# PIC32MZ2048EFM144 register map
Vendor: Microchip
Registers are 32-bit, read-write, reset 0x0 unless marked. A register's access mark holds for its fields unless they carry their own. Addresses are absolute, and some are shared; only a register's first bit layout is shown; [hi:lo] are bit positions; {n}, {i} and the like mark numbered series.

## UART4
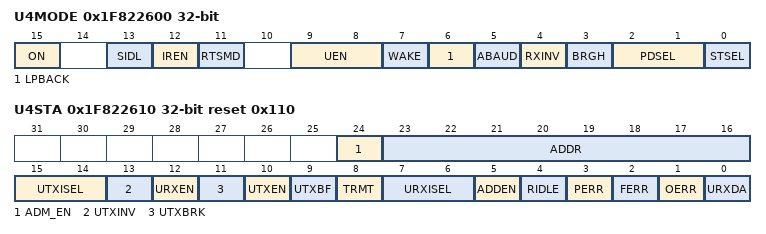
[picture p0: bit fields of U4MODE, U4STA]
0x1F822600 U4MODE
  [15] ON, [13] SIDL, [12] IREN, [11] RTSMD, [9:8] UEN, [7] WAKE, [6] LPBACK, [5] ABAUD, [4] RXINV, [3] BRGH, [2:1] PDSEL, [0] STSEL
0x1F822610 U4STA reset 0x110
  [24] ADM_EN
  [23:16] ADDR
  [15:14] UTXISEL
  [13] UTXINV
  [12] URXEN
  [11] UTXBRK
  [10] UTXEN
  [9] UTXBF ro
  [8] TRMT ro
  [7:6] URXISEL
  [5] ADDEN
  [4] RIDLE ro
  [3] PERR ro
  [2] FERR ro
  [1] OERR — (can only be cleared)
  [0] URXDA ro
0x1F822620 U4TXREG reset not defined — (power-on value -----------------------xxxxxxxxx)
  [8:0] U4TXREG
0x1F822630 U4RXREG ro
  [8:0] U4RXREG
0x1F822640 U4BRG
  [15:0] BRG

## UART5
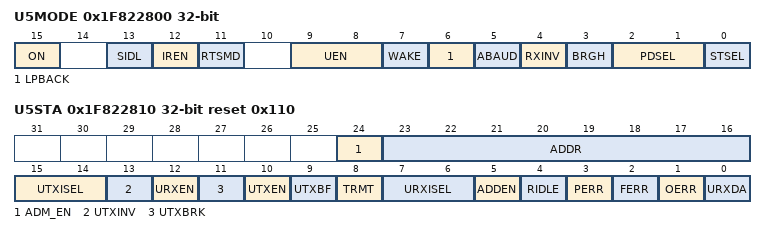
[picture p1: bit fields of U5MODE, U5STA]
0x1F822800 U5MODE
  [15] ON, [13] SIDL, [12] IREN, [11] RTSMD, [9:8] UEN, [7] WAKE, [6] LPBACK, [5] ABAUD, [4] RXINV, [3] BRGH, [2:1] PDSEL, [0] STSEL
0x1F822810 U5STA reset 0x110
  [24] ADM_EN
  [23:16] ADDR
  [15:14] UTXISEL
  [13] UTXINV
  [12] URXEN
  [11] UTXBRK
  [10] UTXEN
  [9] UTXBF ro
  [8] TRMT ro
  [7:6] URXISEL
  [5] ADDEN
  [4] RIDLE ro
  [3] PERR ro
  [2] FERR ro
  [1] OERR — (can only be cleared)
  [0] URXDA ro
0x1F822820 U5TXREG reset not defined — (power-on value -----------------------xxxxxxxxx)
  [8:0] U5TXREG
0x1F822830 U5RXREG ro
  [8:0] U5RXREG
0x1F822840 U5BRG
  [15:0] BRG

## UART6
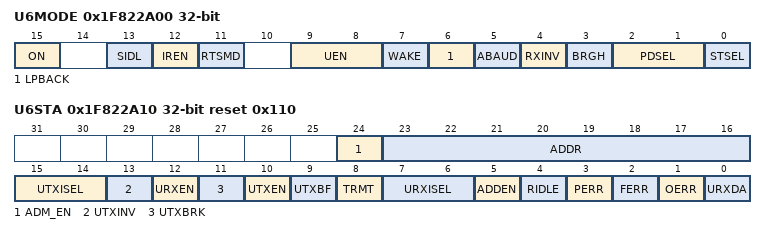
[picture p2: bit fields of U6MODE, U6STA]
0x1F822A00 U6MODE
  [15] ON, [13] SIDL, [12] IREN, [11] RTSMD, [9:8] UEN, [7] WAKE, [6] LPBACK, [5] ABAUD, [4] RXINV, [3] BRGH, [2:1] PDSEL, [0] STSEL
0x1F822A10 U6STA reset 0x110
  [24] ADM_EN
  [23:16] ADDR
  [15:14] UTXISEL
  [13] UTXINV
  [12] URXEN
  [11] UTXBRK
  [10] UTXEN
  [9] UTXBF ro
  [8] TRMT ro
  [7:6] URXISEL
  [5] ADDEN
  [4] RIDLE ro
  [3] PERR ro
  [2] FERR ro
  [1] OERR — (can only be cleared)
  [0] URXDA ro
0x1F822A20 U6TXREG reset not defined — (power-on value -----------------------xxxxxxxxx)
  [8:0] U6TXREG
0x1F822A30 U6RXREG ro
  [8:0] U6RXREG
0x1F822A40 U6BRG
  [15:0] BRG

## PMP
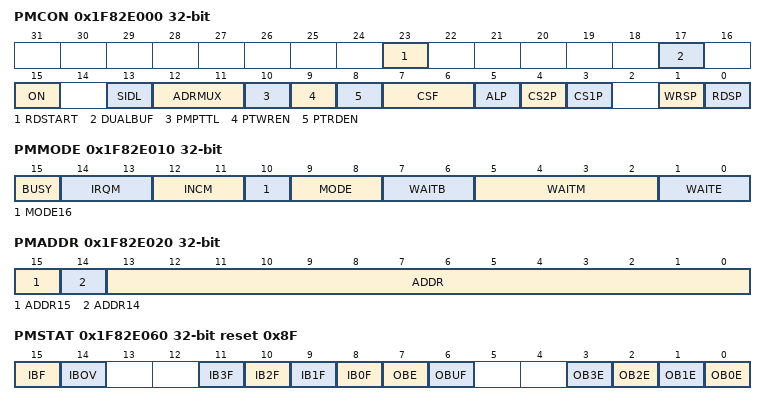
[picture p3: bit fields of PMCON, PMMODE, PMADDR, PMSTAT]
0x1F82E000 PMCON reset not defined — (power-on value --------x-----x-00000-0000000-00)
  [23] RDSTART, [17] DUALBUF, [15] ON, [13] SIDL, [12:11] ADRMUX, [10] PMPTTL, [9] PTWREN, [8] PTRDEN, [7:6] CSF, [5] ALP, [4] CS2P, [3] CS1P, [1] WRSP, [0] RDSP
0x1F82E010 PMMODE
  [15] BUSY, [14:13] IRQM, [12:11] INCM, [10] MODE16, [9:8] MODE, [7:6] WAITB, [5:2] WAITM, [1:0] WAITE
0x1F82E020 PMADDR reset not defined — (power-on value ----------------xxxxxxxxxxxxxxxx)
  [15] ADDR15, [14] ADDR14, [13:0] ADDR
0x1F82E030 PMDOUT reset not defined — (power-on value xxxxxxxxxxxxxxxxxxxxxxxxxxxxxxxx)
  [31:0] DATAOUT
0x1F82E040 PMDIN reset not defined — (power-on value xxxxxxxxxxxxxxxxxxxxxxxxxxxxxxxx)
  [31:0] DATAIN
0x1F82E050 PMAEN reset not defined — (power-on value --------xxxxxxxxxxxxxxxxxxxxxxxx)
  [23:0] PTEN
0x1F82E060 PMSTAT reset 0x8F
  [15] IBF ro, [14] IBOV, [n+8] IB{n}F ro (n=0..3), [7] OBE ro, [6] OBUF, [n] OB{n}E ro (n=0..3)
0x1F82E070 PMWADDR reset not defined — (power-on value --------xxxxxxxxxxxxxxxxxxxxxxxx)
  [23:0] WADDR
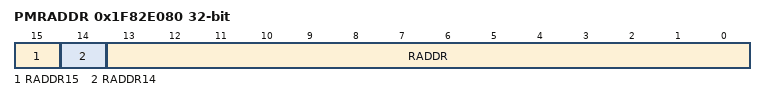
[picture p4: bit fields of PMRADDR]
0x1F82E080 PMRADDR reset not defined — (power-on value ----------------xxxxxxxxxxxxxxxx)
  [15] RADDR15, [14] RADDR14, [13:0] RADDR
0x1F82E090 PMRDIN reset not defined — (power-on value xxxxxxxxxxxxxxxxxxxxxxxxxxxxxxxx)
  [31:0] RDATAIN

## TMR1
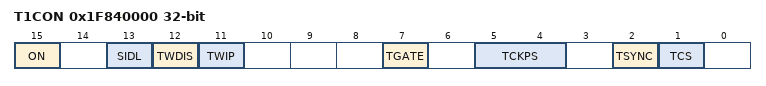
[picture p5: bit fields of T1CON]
0x1F840000 T1CON
  [15] ON, [13] SIDL, [12] TWDIS, [11] TWIP ro, [7] TGATE, [5:4] TCKPS, [2] TSYNC, [1] TCS
0x1F840010 TMR1
0x1F840020 PR1 reset 0xFFFF

## TMR2
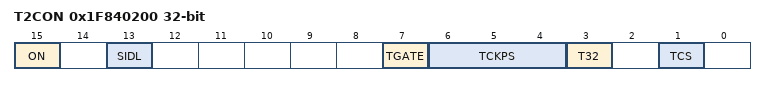
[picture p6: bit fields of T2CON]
0x1F840200 T2CON
  [15] ON, [13] SIDL, [7] TGATE, [6:4] TCKPS, [3] T32, [1] TCS
0x1F840210 TMR2
0x1F840220 PR2 reset 0xFFFF

## TMR3
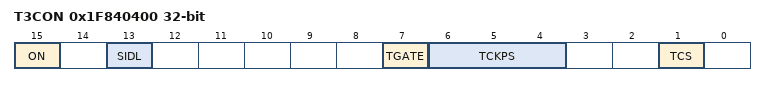
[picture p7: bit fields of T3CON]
0x1F840400 T3CON
  [15] ON, [13] SIDL, [7] TGATE, [6:4] TCKPS, [1] TCS
0x1F840410 TMR3
0x1F840420 PR3 reset 0xFFFF
